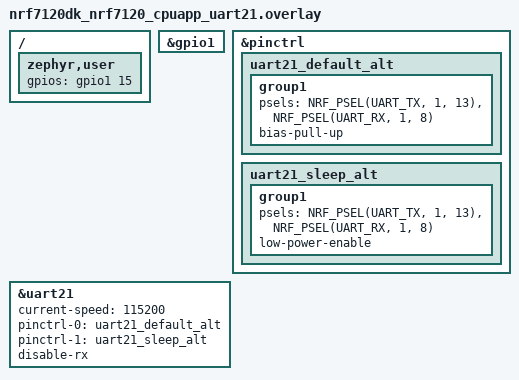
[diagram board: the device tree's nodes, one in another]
/*
 * Test requires wire connection between:
 *  - uart21 TX at P1.13 <-> GPIO input at P1.15
 */

/ {
	zephyr,user {
		gpios = <&gpio1 15 GPIO_ACTIVE_HIGH>;
	};
};

&gpio1 {
	status = "okay";
};

&pinctrl {
	uart21_default_alt: uart21_default_alt {
		group1 {
			psels = <NRF_PSEL(UART_TX, 1, 13)>,
				<NRF_PSEL(UART_RX, 1, 8)>;
			bias-pull-up;
		};
	};

	uart21_sleep_alt: uart21_sleep_alt {
		group1 {
			psels = <NRF_PSEL(UART_TX, 1, 13)>,
				<NRF_PSEL(UART_RX, 1, 8)>;
			low-power-enable;
		};
	};
};

dut: &uart21 {
	status = "okay";
	current-speed = <115200>;
	pinctrl-0 = <&uart21_default_alt>;
	pinctrl-1 = <&uart21_sleep_alt>;
	pinctrl-names = "default", "sleep";
	disable-rx;
};
